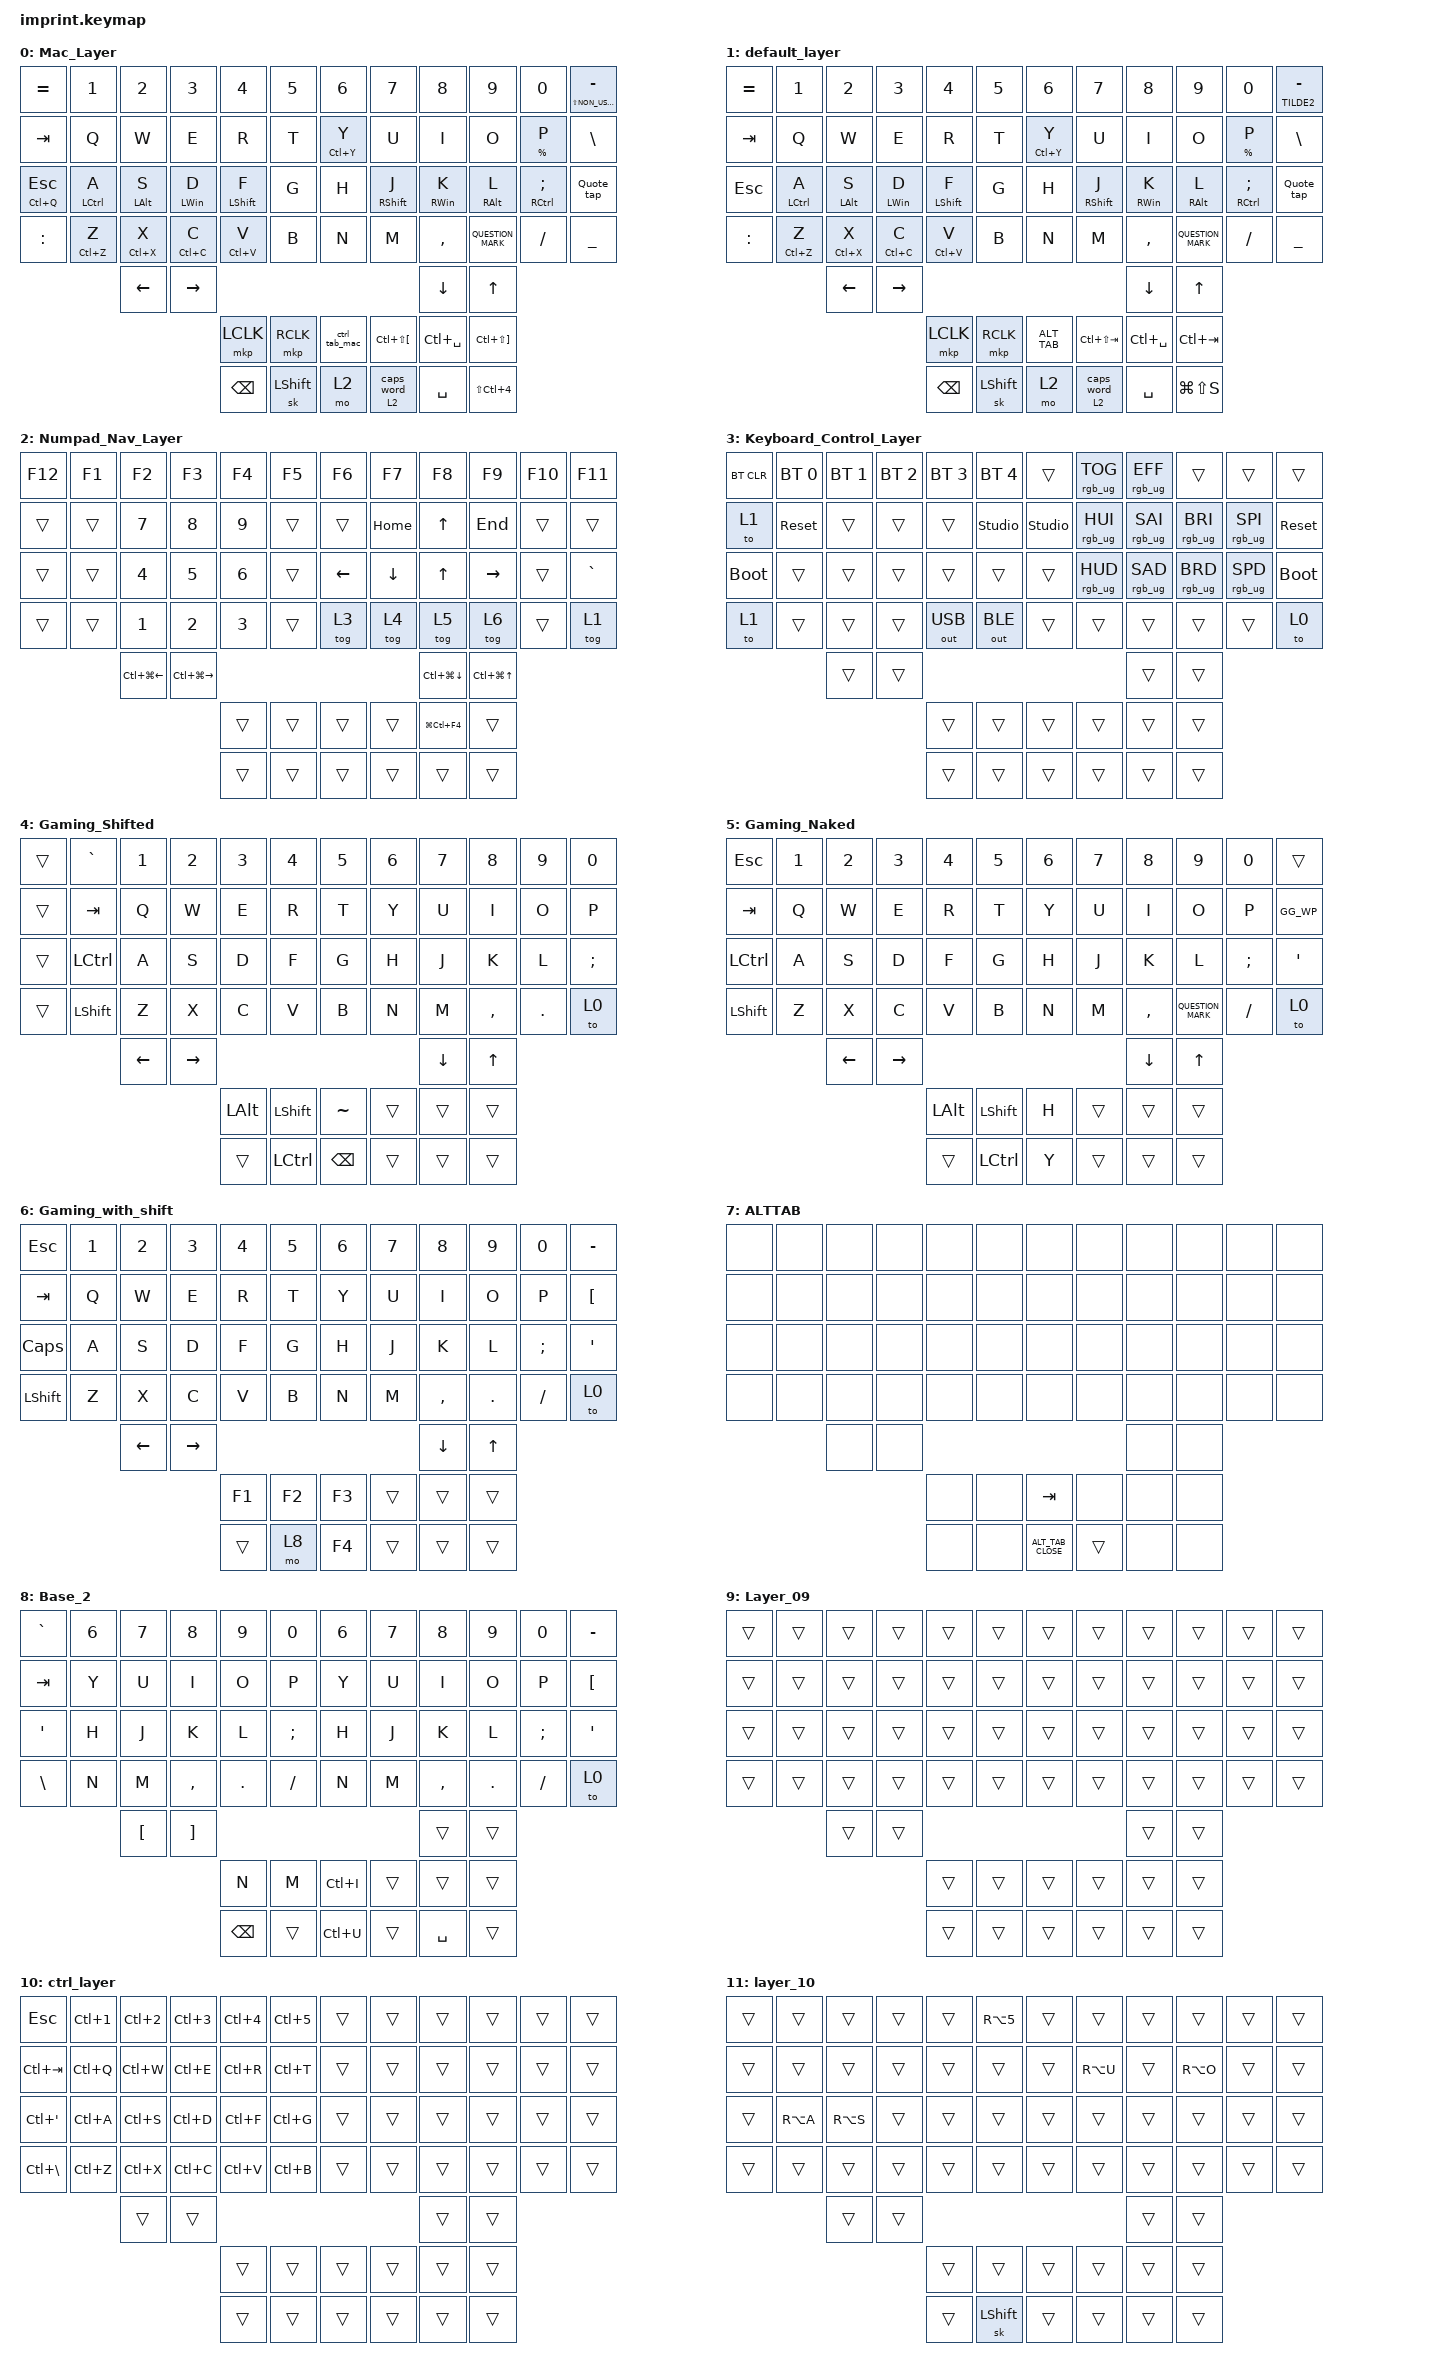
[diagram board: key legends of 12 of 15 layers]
#include <input/processors.dtsi>
#include <dt-bindings/zmk/input_transform.h>
#include <behaviors.dtsi>
#include <dt-bindings/zmk/bt.h>
#include <dt-bindings/zmk/keys.h>
#include <dt-bindings/zmk/outputs.h>
#include <dt-bindings/zmk/pointing.h>
#include <dt-bindings/zmk/rgb.h>

&sk { quick-release; };

/ {
    chosen { zmk,matrix-transform = &imprint_number_row; };

    combos {
        compatible = "zmk,combos";

        enter {
            bindings = <&kp ENTER>;
            key-positions = <33 34>;
        };

        Left_Parenth {
            bindings = <&kp LEFT_PARENTHESIS>;
            key-positions = <16 17>;
            layers = <1 0>;
            require-prior-idle-ms = <250>;
            timeout-ms = <50>;
        };

        Right_Parenth {
            bindings = <&kp RIGHT_PARENTHESIS>;
            key-positions = <18 19>;
            layers = <1 0>;
            timeout-ms = <50>;
            require-prior-idle-ms = <250>;
        };

        Left_Curly {
            bindings = <&kp LEFT_BRACE>;
            key-positions = <28 29>;
            layers = <1 0>;
            timeout-ms = <50>;
            require-prior-idle-ms = <250>;
        };

        Right_Curly {
            bindings = <&kp RIGHT_BRACE>;
            key-positions = <30 31>;
            layers = <1 0>;
            timeout-ms = <50>;
            require-prior-idle-ms = <250>;
        };

        Left_Bracket {
            bindings = <&kp LEFT_BRACKET>;
            key-positions = <40 41>;
            layers = <1 0>;
            timeout-ms = <50>;
            require-prior-idle-ms = <250>;
        };

        Right_Bracket {
            bindings = <&kp RIGHT_BRACKET>;
            key-positions = <42 43>;
            timeout-ms = <50>;
            require-prior-idle-ms = <250>;
            layers = <1 0>;
        };

        LEFT_LESS {
            bindings = <&kp LESS_THAN>;
            key-positions = <16 15>;
            layers = <1 0>;
            timeout-ms = <50>;
            require-prior-idle-ms = <250>;
        };

        RIGHT_GREATER {
            bindings = <&kp GREATER_THAN>;
            key-positions = <19 20>;
            layers = <1 0>;
            timeout-ms = <50>;
            require-prior-idle-ms = <250>;
        };

        COMBO_CARET {
            bindings = <&kp CARET>;
            key-positions = <16 15 19 20>;
            layers = <1 0>;
        };

        German_Chars {
            bindings = <&sl 11>;
            key-positions = <59 62>;
            layers = <1>;
        };

        Middle_Click_Combo {
            bindings = <&mkp MCLK>;
            key-positions = <53 52>;
        };

        DELETE_COMBO {
            bindings = <&kp DELETE>;
            key-positions = <58 59>;
        };

        KP_SHIFT_ENTER {
            bindings = <&kp LS(RET)>;
            key-positions = <45 46>;
        };

        GERMAN_CHARS_MAC {
            bindings = <&kp LA(U)>;
            key-positions = <59 62>;
            layers = <0>;
        };
    };

    behaviors {
        L_Ctrl: L_Ctrl {
            compatible = "zmk,behavior-hold-tap";
            label = "L_CTRL";
            bindings = <&kp>, <&kp>;

            #binding-cells = <2>;
            hold-trigger-key-positions = <25>;
            tapping-term-ms = <280>;
            flavor = "balanced";
            require-prior-idle-ms = <250>;
        };

        L_ALT: L_ALT {
            compatible = "zmk,behavior-hold-tap";
            label = "L_ALT";
            bindings = <&kp>, <&kp>;

            #binding-cells = <2>;
            hold-trigger-key-positions = <26>;
            tapping-term-ms = <280>;
            flavor = "balanced";
            require-prior-idle-ms = <250>;
        };

        L_OS: L_OS {
            compatible = "zmk,behavior-hold-tap";
            label = "L_OS";
            bindings = <&kp>, <&kp>;

            #binding-cells = <2>;
            tapping-term-ms = <280>;
            flavor = "balanced";
            hold-trigger-key-positions = <27>;
            require-prior-idle-ms = <250>;
        };

        L_SHIFT: L_SHIFT {
            compatible = "zmk,behavior-hold-tap";
            label = "L_SHIFT";
            bindings = <&kp>, <&kp>;

            #binding-cells = <2>;
            tapping-term-ms = <280>;
            flavor = "hold-preferred";
            hold-trigger-key-positions = <28>;
            hold-while-undecided;
            require-prior-idle-ms = <250>;
        };

        R_CTRL: R_CTRL {
            compatible = "zmk,behavior-hold-tap";
            label = "R_CTRL";
            bindings = <&kp>, <&kp>;

            #binding-cells = <2>;
            hold-trigger-key-positions = <34>;
            tapping-term-ms = <280>;
            flavor = "balanced";
            require-prior-idle-ms = <250>;
        };

        R_ALT: R_ALT {
            compatible = "zmk,behavior-hold-tap";
            label = "R_ALT";
            bindings = <&kp>, <&kp>;

            #binding-cells = <2>;
            hold-trigger-key-positions = <33>;
            tapping-term-ms = <280>;
            flavor = "balanced";
            require-prior-idle-ms = <250>;
        };

        R_OS: R_OS {
            compatible = "zmk,behavior-hold-tap";
            label = "R_OS";
            bindings = <&kp>, <&kp>;

            #binding-cells = <2>;
            hold-trigger-key-positions = <32>;
            tapping-term-ms = <280>;
            flavor = "balanced";
            require-prior-idle-ms = <250>;
        };

        R_SHIFT: R_SHIFT {
            compatible = "zmk,behavior-hold-tap";
            label = "R_SHIFT";
            bindings = <&kp>, <&kp>;

            #binding-cells = <2>;
            hold-trigger-key-positions = <31>;
            tapping-term-ms = <280>;
            flavor = "hold-preferred";
            hold-while-undecided;
            require-prior-idle-ms = <250>;
        };

        C_COPY: C_COPY {
            compatible = "zmk,behavior-hold-tap";
            label = "C_COPY";
            bindings = <&kp>, <&kp>;

            #binding-cells = <2>;
            tapping-term-ms = <250>;
            hold-trigger-key-positions = <39>;
            flavor = "balanced";
            require-prior-idle-ms = <250>;
        };

        V_PASTE: V_PASTE {
            compatible = "zmk,behavior-hold-tap";
            label = "V_PASTE";
            bindings = <&kp>, <&kp>;

            #binding-cells = <2>;
            tapping-term-ms = <250>;
            hold-trigger-key-positions = <40>;
            flavor = "balanced";
            require-prior-idle-ms = <250>;
        };

        SCREAMING_PERIOD: SCREAMING_PERIOD {
            compatible = "zmk,behavior-hold-tap";
            label = "SCREAMING_PERIOD";
            bindings = <&kp>, <&kp>;

            #binding-cells = <2>;
            tapping-term-ms = <210>;
            flavor = "hold-preferred";
        };

        KEYBOARD_SETTINGS: KEYBOARD_SETTINGS {
            compatible = "zmk,behavior-tap-dance";
            label = "KEYBOARD_SETTINGS";
            #binding-cells = <0>;
            bindings = <&MOD_LAYER>, <&tog 3>;
        };

        QUESTION_MARK: QUESTION_MARK {
            compatible = "zmk,behavior-tap-dance";
            label = "QUESTION_MARK";
            #binding-cells = <0>;
            bindings = <&SCREAMING_PERIOD EXCL PERIOD>, <&kp QUESTION>;

            tapping-term-ms = <250>;
        };

        Z_Undo: Z_Undo {
            compatible = "zmk,behavior-hold-tap";
            label = "Z_UNDO";
            bindings = <&kp>, <&kp>;

            #binding-cells = <2>;
            tapping-term-ms = <250>;
            hold-trigger-key-positions = <37>;
            flavor = "balanced";
            require-prior-idle-ms = <250>;
        };

        Quote_tap: Quote_tap {
            compatible = "zmk,behavior-tap-dance";
            label = "QUOTE_TAP";
            #binding-cells = <0>;
            bindings =
                <&kp SINGLE_QUOTE>,
                <&GRAVE_SYMBOL NON_US_BACKSLASH DOUBLE_QUOTES>;
        };

        Caps_Word_tapdance: Caps_Word_tapdance {
            compatible = "zmk,behavior-hold-tap";
            label = "CAPS_WORD_TAPDANCE";
            bindings = <&mo>, <&caps_word>;

            #binding-cells = <2>;
            tapping-term-ms = <250>;
            hold-trigger-key-positions = <61>;
            flavor = "balanced";
            require-prior-idle-ms = <250>;
        };

        GRAVE_SYMBOL: GRAVE_SYMBOL {
            compatible = "zmk,behavior-hold-tap";
            label = "GRAVE_SYMBOL";
            bindings = <&kp>, <&kp>;

            #binding-cells = <2>;
            tapping-term-ms = <210>;
            flavor = "balanced";
        };

        dash_tilde: dash_tilde {
            compatible = "zmk,behavior-hold-tap";
            label = "DASH_TILDE";
            bindings = <&kp>, <&kp>;

            #binding-cells = <2>;
            tapping-term-ms = <210>;
            flavor = "balanced";
        };

        ESCAPE_QUIT: ESCAPE_QUIT {
            compatible = "zmk,behavior-hold-tap";
            label = "ESCAPE_QUIT";
            bindings = <&kp>, <&kp>;

            #binding-cells = <2>;
            tapping-term-ms = <210>;
            flavor = "balanced";
        };
    };

    macros {
        ALT_TAB: ALT_TAB {
            compatible = "zmk,behavior-macro";
            #binding-cells = <0>;
            bindings = <&kt LEFT_ALT &kp TAB &to 7>;
            label = "ALT_TAB";
            wait-ms = <40>;
        };

        ALT_TAB_CLOSE: ALT_TAB_CLOSE {
            compatible = "zmk,behavior-macro";
            #binding-cells = <0>;
            bindings = <&kt LEFT_ALT &to 1>;
            label = "ALT_TAB_CLOSE";
        };

        GG_WP: GG_WP {
            compatible = "zmk,behavior-macro";
            #binding-cells = <0>;
            bindings = <&kp RS(ENTER) &kp LS(G) &kp LS(G) &kp SPACE &kp LS(W) &kp LS(P) &kp ENTER>;
            label = "GG_WP";
        };

        HOME_LAYER: HOME_LAYER {
            compatible = "zmk,behavior-macro";
            #binding-cells = <0>;
            bindings = <&to 1>;
            label = "HOME_LAYER";
        };

        MOD_LAYER: MOD_LAYER {
            compatible = "zmk,behavior-macro";
            #binding-cells = <0>;
            bindings =
                <&macro_press>,
                <&mo 2>,
                <&macro_tap>,
                <&macro_pause_for_release>,
                <&macro_release>,
                <&mo 2>,
                <&macro_tap>;

            label = "MOD_LAYER";
        };

        ctrl_tab_mac: ctrl_tab_mac {
            compatible = "zmk,behavior-macro";
            #binding-cells = <0>;
            bindings = <&kt LCTRL &kp TAB &to 14>;
            label = "CTRL_TAB_MAC";
            wait-ms = <40>;
        };

        ctrl_tab_close_mac: ctrl_tab_close_mac {
            compatible = "zmk,behavior-macro";
            #binding-cells = <0>;
            bindings = <&kt LCTRL &kp LEFT_ALT &to 0>;
            label = "CTRL_TAB_CLOSE_MAC";
            wait-ms = <40>;
        };
    };

    keymap {
        compatible = "zmk,keymap";

        Mac_Layer {
            bindings = <
&kp EQUAL                  &kp N1           &kp N2             &kp N3            &kp N4                 &kp N5                           &kp N6                    &kp N7                  &kp N8                     &kp N9              &kp N0                   &dash_tilde LS(NON_US_BACKSLASH) MINUS
&kp TAB                    &kp Q            &kp W              &kp E             &kp R                  &kp T                            &Z_Undo LC(Y) Y           &kp U                   &kp I                      &kp O               &Z_Undo PERCENT P        &kp BSLH
&ESCAPE_QUIT LC(Q) ESCAPE  &L_Ctrl LCTRL A  &L_ALT LEFT_ALT S  &L_OS LEFT_WIN D  &L_SHIFT LEFT_SHIFT F  &kp G                            &kp H                     &R_SHIFT RIGHT_SHIFT J  &R_OS RIGHT_WIN K          &R_ALT RIGHT_ALT L  &R_CTRL RCTRL SEMICOLON  &Quote_tap
&kp COLON                  &Z_Undo LC(Z) Z  &Z_Undo LC(X) X    &C_COPY LC(C) C   &V_PASTE LC(V) V       &kp B                            &kp N                     &kp M                   &kp COMMA                  &QUESTION_MARK      &kp FSLH                 &kp UNDERSCORE
                                            &kp LEFT_ARROW     &kp RIGHT_ARROW                                                                                                             &kp DOWN_ARROW             &kp UP_ARROW
                                                                                 &mkp LCLK              &mkp RCLK       &ctrl_tab_mac    &kp LC(LS(LEFT_BRACKET))  &kp LC(SPACE)           &kp LC(LS(RIGHT_BRACKET))
                                                                                 &kp BACKSPACE          &sk LEFT_SHIFT  &mo 2            &Caps_Word_tapdance 2 0   &kp SPACE               &kp LS(LC(NUMBER_4))
            >;
        };

        default_layer {
            bindings = <
&kp EQUAL  &kp N1           &kp N2             &kp N3            &kp N4                 &kp N5                      &kp N6                   &kp N7                  &kp N8             &kp N9              &kp N0                   &dash_tilde TILDE2 MINUS
&kp TAB    &kp Q            &kp W              &kp E             &kp R                  &kp T                       &Z_Undo LC(Y) Y          &kp U                   &kp I              &kp O               &Z_Undo PERCENT P        &kp BSLH
&kp ESC    &L_Ctrl LCTRL A  &L_ALT LEFT_ALT S  &L_OS LEFT_WIN D  &L_SHIFT LEFT_SHIFT F  &kp G                       &kp H                    &R_SHIFT RIGHT_SHIFT J  &R_OS RIGHT_WIN K  &R_ALT RIGHT_ALT L  &R_CTRL RCTRL SEMICOLON  &Quote_tap
&kp COLON  &Z_Undo LC(Z) Z  &Z_Undo LC(X) X    &C_COPY LC(C) C   &V_PASTE LC(V) V       &kp B                       &kp N                    &kp M                   &kp COMMA          &QUESTION_MARK      &kp FSLH                 &kp UNDERSCORE
                            &kp LEFT_ARROW     &kp RIGHT_ARROW                                                                                                       &kp DOWN_ARROW     &kp UP_ARROW
                                                                 &mkp LCLK              &mkp RCLK       &ALT_TAB    &kp LC(LS(TAB))          &kp LC(SPACE)           &kp LC(TAB)
                                                                 &kp BACKSPACE          &sk LEFT_SHIFT  &mo 2       &Caps_Word_tapdance 2 0  &kp SPACE               &kp LG(LS(S))
            >;
        };

        Numpad_Nav_Layer {
            bindings = <
&kp F12  &kp F1  &kp F2                  &kp F3             &kp F4  &kp F5            &kp F6          &kp F7          &kp F8            &kp F9                &kp F10  &kp F11
&trans   &trans  &kp N7                  &kp N8             &kp N9  &trans            &trans          &kp HOME        &kp UP            &kp END               &trans   &trans
&trans   &trans  &kp N4                  &kp N5             &kp N6  &trans            &kp LEFT_ARROW  &kp DOWN        &kp UP_ARROW      &kp RIGHT             &trans   &kp GRAVE
&trans   &trans  &kp N1                  &kp N2             &kp N3  &trans            &tog 3          &tog 4          &tog 5            &tog 6                &trans   &tog 1
                 &kp LC(LG(LEFT_ARROW))  &kp LC(LG(RIGHT))                                                            &kp LC(LG(DOWN))  &kp LC(LG(UP_ARROW))
                                                            &trans  &trans  &trans    &trans          &kp LG(LC(F4))  &trans
                                                            &trans  &trans  &trans    &trans          &trans          &trans
            >;
        };

        Keyboard_Control_Layer {
            bindings = <
&bt BT_CLR   &bt BT_SEL 0  &bt BT_SEL 1  &bt BT_SEL 2  &bt BT_SEL 3  &bt BT_SEL 4              &trans          &rgb_ug RGB_TOG  &rgb_ug RGB_EFF  &trans           &trans           &trans
&to 1        &sys_reset    &trans        &trans        &trans        &studio_unlock            &studio_unlock  &rgb_ug RGB_HUI  &rgb_ug RGB_SAI  &rgb_ug RGB_BRI  &rgb_ug RGB_SPI  &sys_reset
&bootloader  &trans        &trans        &trans        &trans        &trans                    &trans          &rgb_ug RGB_HUD  &rgb_ug RGB_SAD  &rgb_ug RGB_BRD  &rgb_ug RGB_SPD  &bootloader
&to 1        &trans        &trans        &trans        &out OUT_USB  &out OUT_BLE              &trans          &trans           &trans           &trans           &trans           &to 0
                           &trans        &trans                                                                                 &trans           &trans
                                                       &trans        &trans          &trans    &trans          &trans           &trans
                                                       &trans        &trans          &trans    &trans          &trans           &trans
            >;
        };

        Gaming_Shifted {
            bindings = <
&trans  &kp GRAVE  &kp N1    &kp N2     &kp N3    &kp N4                             &kp N5  &kp N6  &kp N7    &kp N8     &kp N9   &kp N0
&trans  &kp TAB    &kp Q     &kp W      &kp E     &kp R                              &kp T   &kp Y   &kp U     &kp I      &kp O    &kp P
&trans  &kp LCTRL  &kp A     &kp S      &kp D     &kp F                              &kp G   &kp H   &kp J     &kp K      &kp L    &kp SEMI
&trans  &kp LSHFT  &kp Z     &kp X      &kp C     &kp V                              &kp B   &kp N   &kp M     &kp COMMA  &kp DOT  &to 0
                   &kp LEFT  &kp RIGHT                                                               &kp DOWN  &kp UP
                                        &kp LALT  &kp LSHFT         &kp TILDE        &trans  &trans  &trans
                                        &trans    &kp LEFT_CONTROL  &kp BACKSPACE    &trans  &trans  &trans
            >;
        };

        Gaming_Naked {
            bindings = <
&kp ESC    &kp N1  &kp N2    &kp N3     &kp N4        &kp N5                   &kp N6  &kp N7  &kp N8     &kp N9          &kp N0    &trans
&kp TAB    &kp Q   &kp W     &kp E      &kp R         &kp T                    &kp Y   &kp U   &kp I      &kp O           &kp P     &GG_WP
&kp LCTRL  &kp A   &kp S     &kp D      &kp F         &kp G                    &kp H   &kp J   &kp K      &kp L           &kp SEMI  &kp APOS
&kp LSHFT  &kp Z   &kp X     &kp C      &kp V         &kp B                    &kp N   &kp M   &kp COMMA  &QUESTION_MARK  &kp FSLH  &to 0
                   &kp LEFT  &kp RIGHT                                                         &kp DOWN   &kp UP
                                        &kp LEFT_ALT  &kp LEFT_SHIFT  &kp H    &trans  &trans  &trans
                                        &trans        &kp LCTRL       &kp Y    &trans  &trans  &trans
            >;
        };

        Gaming_with_shift {
            bindings = <
&kp ESC    &kp N1  &kp N2    &kp N3     &kp N4  &kp N5            &kp N6  &kp N7  &kp N8     &kp N9   &kp N0    &kp MINUS
&kp TAB    &kp Q   &kp W     &kp E      &kp R   &kp T             &kp Y   &kp U   &kp I      &kp O    &kp P     &kp LBKT
&kp CAPS   &kp A   &kp S     &kp D      &kp F   &kp G             &kp H   &kp J   &kp K      &kp L    &kp SEMI  &kp APOS
&kp LSHFT  &kp Z   &kp X     &kp C      &kp V   &kp B             &kp N   &kp M   &kp COMMA  &kp DOT  &kp FSLH  &to 0
                   &kp LEFT  &kp RIGHT                                            &kp DOWN   &kp UP
                                        &kp F1  &kp F2  &kp F3    &trans  &trans  &trans
                                        &trans  &mo 8   &kp F4    &trans  &trans  &trans
            >;
        };

        ALTTAB {
            bindings = <
&none  &none  &none  &none  &none  &none                    &none   &none  &none  &none  &none  &none
&none  &none  &none  &none  &none  &none                    &none   &none  &none  &none  &none  &none
&none  &none  &none  &none  &none  &none                    &none   &none  &none  &none  &none  &none
&none  &none  &none  &none  &none  &none                    &none   &none  &none  &none  &none  &none
              &none  &none                                                 &none  &none
                            &none  &none  &kp TAB           &none   &none  &none
                            &none  &none  &ALT_TAB_CLOSE    &trans  &none  &none
            >;
        };

        Base_2 {
            bindings = <
&kp GRAVE         &kp NUMBER_6  &kp N7            &kp N8             &kp N9      &kp N0                      &kp N6  &kp N7     &kp N8     &kp N9   &kp N0    &kp MINUS
&kp TAB           &kp Y         &kp U             &kp I              &kp O       &kp P                       &kp Y   &kp U      &kp I      &kp O    &kp P     &kp LBKT
&kp SINGLE_QUOTE  &kp H         &kp J             &kp K              &kp L       &kp SEMICOLON               &kp H   &kp J      &kp K      &kp L    &kp SEMI  &kp APOS
&kp BSLH          &kp N         &kp M             &kp COMMA          &kp PERIOD  &kp SLASH                   &kp N   &kp M      &kp COMMA  &kp DOT  &kp FSLH  &to 0
                                &kp LEFT_BRACKET  &kp RIGHT_BRACKET                                                             &trans     &trans
                                                                     &kp N       &kp M          &kp LC(I)    &trans  &trans     &trans
                                                                     &kp BSPC    &trans         &kp LC(U)    &trans  &kp SPACE  &trans
            >;
        };

        Layer_09 {
            bindings = <
&trans  &trans  &trans  &trans  &trans  &trans            &trans  &trans  &trans  &trans  &trans  &trans
&trans  &trans  &trans  &trans  &trans  &trans            &trans  &trans  &trans  &trans  &trans  &trans
&trans  &trans  &trans  &trans  &trans  &trans            &trans  &trans  &trans  &trans  &trans  &trans
&trans  &trans  &trans  &trans  &trans  &trans            &trans  &trans  &trans  &trans  &trans  &trans
                &trans  &trans                                            &trans  &trans
                                &trans  &trans  &trans    &trans  &trans  &trans
                                &trans  &trans  &trans    &trans  &trans  &trans
            >;
        };

        ctrl_layer {
            bindings = <
&kp ESC               &kp LC(N1)  &kp LC(N2)  &kp LC(N3)  &kp LC(N4)  &kp LC(N5)            &trans  &trans  &trans  &trans  &trans  &trans
&kp LC(TAB)           &kp LC(Q)   &kp LC(W)   &kp LC(E)   &kp LC(R)   &kp LC(T)             &trans  &trans  &trans  &trans  &trans  &trans
&kp LC(SINGLE_QUOTE)  &kp LC(A)   &kp LC(S)   &kp LC(D)   &kp LC(F)   &kp LC(G)             &trans  &trans  &trans  &trans  &trans  &trans
&kp LC(BACKSLASH)     &kp LC(Z)   &kp LC(X)   &kp LC(C)   &kp LC(V)   &kp LC(B)             &trans  &trans  &trans  &trans  &trans  &trans
                                  &trans      &trans                                                        &trans  &trans
                                                          &trans      &trans      &trans    &trans  &trans  &trans
                                                          &trans      &trans      &trans    &trans  &trans  &trans
            >;
        };

        layer_10 {
            bindings = <
&trans  &trans     &trans     &trans  &trans  &kp RA(NUMBER_5)            &trans  &trans     &trans  &trans     &trans  &trans
&trans  &trans     &trans     &trans  &trans  &trans                      &trans  &kp RA(U)  &trans  &kp RA(O)  &trans  &trans
&trans  &kp RA(A)  &kp RA(S)  &trans  &trans  &trans                      &trans  &trans     &trans  &trans     &trans  &trans
&trans  &trans     &trans     &trans  &trans  &trans                      &trans  &trans     &trans  &trans     &trans  &trans
                   &trans     &trans                                                         &trans  &trans
                                      &trans  &trans            &trans    &trans  &trans     &trans
                                      &trans  &sk LEFT_SHIFT    &trans    &trans  &trans     &trans
            >;
        };

        layer_11 {
            bindings = <
&trans  &trans  &trans  &trans  &trans  &trans            &trans  &trans  &trans  &trans  &trans  &trans
&trans  &trans  &trans  &trans  &trans  &trans            &trans  &trans  &trans  &trans  &trans  &trans
&trans  &trans  &trans  &trans  &trans  &trans            &trans  &trans  &trans  &trans  &trans  &trans
&trans  &trans  &trans  &trans  &trans  &trans            &trans  &trans  &trans  &trans  &trans  &trans
                &trans  &trans                                            &trans  &trans
                                &trans  &trans  &trans    &trans  &trans  &trans
                                &trans  &trans  &trans    &trans  &trans  &trans
            >;
        };

        Auto_Mouse_Layer {
            bindings = <
&trans  &trans  &trans     &trans     &trans     &trans            &trans  &trans  &trans  &trans  &trans  &trans
&trans  &trans  &trans     &trans     &trans     &trans            &trans  &trans  &trans  &trans  &trans  &trans
&trans  &trans  &mkp LCLK  &mkp MCLK  &mkp RCLK  &trans            &trans  &trans  &trans  &trans  &trans  &trans
&trans  &trans  &trans     &trans     &trans     &trans            &trans  &trans  &trans  &trans  &trans  &trans
                &trans     &trans                                                  &trans  &trans
                                      &trans     &trans  &trans    &trans  &trans  &trans
                                      &trans     &trans  &trans    &trans  &trans  &trans
            >;
        };

        layer_14 {
            bindings = <
&trans  &trans  &trans  &trans  &trans  &trans                         &trans  &trans  &trans  &trans  &trans  &trans
&trans  &trans  &trans  &trans  &trans  &trans                         &trans  &trans  &trans  &trans  &trans  &trans
&trans  &trans  &trans  &trans  &trans  &trans                         &trans  &trans  &trans  &trans  &trans  &trans
&trans  &trans  &trans  &trans  &trans  &trans                         &trans  &trans  &trans  &trans  &trans  &to 0
                &trans  &trans                                                         &trans  &trans
                                &trans  &trans  &kp TAB                &trans  &trans  &trans
                                &trans  &trans  &ctrl_tab_close_mac    &trans  &trans  &trans
            >;
        };
    };
};

// left hand trackball configuration (unused)
// &trackball_central_listener {
// };
// right hand trackball configuration

&trackball_peripheral_listener {
    input-processors = <&zip_xy_scaler 2 3>;

    scroller {
        layers = <2 8>;
        input-processors = <&zip_xy_scaler 1 60>, <&zip_xy_to_scroll_mapper>;
    };
};
